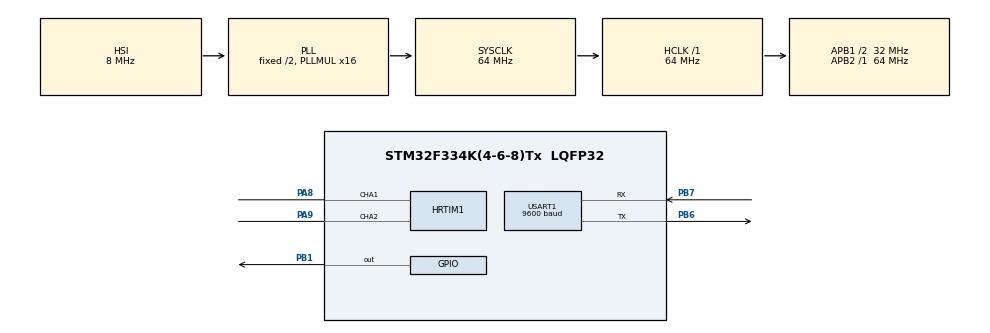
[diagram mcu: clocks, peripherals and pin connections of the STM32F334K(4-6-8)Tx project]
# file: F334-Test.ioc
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HRTIM1.CompareUnit1-Output_TA1TA2=HRTIM_COMPAREUNIT_1
HRTIM1.CompareUnit2-Output_TA1TA2=__NULL
HRTIM1.CompareValue1-Output_TA1TA2=96
HRTIM1.CompareValue2-Output_TA1TA2=5000
HRTIM1.Configuration_TA=Waveform
HRTIM1.DeadTimeInsertion-Output_TA1TA2=HRTIM_TIMDEADTIMEINSERTION_ENABLED
HRTIM1.Deadtimeconfig-Output_TA1TA2=HRTIM_TIMERINDEX_TIMER_A
HRTIM1.FallingValue-Output_TA1TA2=400
HRTIM1.InterruptRequests1-Output_TA1TA2=HRTIM_TIM_IT_UPD
HRTIM1.NumberInterruptRequests-Output_TA1TA2=1
HRTIM1.NumberResetSource1-Output_TA1TA2=1
HRTIM1.NumberResetSource2_TA=0
HRTIM1.NumberSetSource1-Output_TA1TA2=1
HRTIM1.NumberSetSource2_TA=0
HRTIM1.PWMChannel_TA1=HRTIM_OUTPUT_TA1
HRTIM1.PWMChannel_TA2=HRTIM_OUTPUT_TA2
HRTIM1.PWMPolarity_TA2=HRTIM_OUTPUTPOLARITY_LOW
HRTIM1.PWMPulse_TA1=5000
HRTIM1.Periode_MASTER=40960
HRTIM1.Periode_TA=40960
HRTIM1.Polarity2-Output_TA1TA2=HRTIM_OUTPUTPOLARITY_HIGH
HRTIM1.PreloadEnable-Output_TA1TA2=HRTIM_PRELOAD_ENABLED
HRTIM1.PrescalerDead-Output_TA1TA2=HRTIM_TIMDEADTIME_PRESCALERRATIO_MUL8
HRTIM1.RepetitionUpdate-Output_TA1TA2=HRTIM_UPDATEONREPETITION_ENABLED
HRTIM1.ResetOutput1_Source1-Output_TA1TA2=HRTIM_OUTPUTRESET_TIMCMP1
HRTIM1.ResetOutput2_Source1-Output_TA1TA2=HRTIM_OUTPUTRESET_TIMCMP1
HRTIM1.RisingValue-Output_TA1TA2=400
HRTIM1.SetOutput1_Source1-Output_TA1TA2=HRTIM_OUTPUTSET_TIMPER
HRTIM1.SetOutput2_Source1-Output_TA1TA2=HRTIM_OUTPUTSET_TIMCMP1
Mcu.Family=STM32F3
Mcu.Name=STM32F334K(4-6-8)Tx
Mcu.Package=LQFP32
NVIC.HRTIM1_TIMA_IRQn=true\:0\:0\:false\:false\:true\:true\:true
NVIC.PriorityGroup=NVIC_PRIORITYGROUP_3
PA13.Mode=Serial_Wire
PA13.Signal=SYS_JTMS-SWDIO
PA14.Mode=Serial_Wire
PA14.Signal=SYS_JTCK-SWCLK
PA8.Mode=Output_TA1TA2
PA8.Signal=HRTIM1_CHA1
PA9.Mode=Output_TA1TA2
PA9.Signal=HRTIM1_CHA2
PB1.GPIO_Speed=GPIO_SPEED_FREQ_HIGH
PB1.Signal=GPIO_Output
PB6.Mode=Asynchronous
PB6.Signal=USART1_TX
PB7.Mode=Asynchronous
PB7.Signal=USART1_RX
ProjectManager.HeapSize=0x200
ProjectManager.StackSize=0x400
ProjectManager.TargetToolchain=Makefile
RCC.AHBFreq_Value=64000000
RCC.APB1CLKDivider=RCC_HCLK_DIV2
RCC.APB1Freq_Value=32000000
RCC.APB1TimFreq_Value=64000000
RCC.APB2Freq_Value=64000000
RCC.APB2TimFreq_Value=64000000
RCC.CortexFreq_Value=64000000
RCC.HCLKFreq_Value=64000000
RCC.HRTIMSelection=RCC_HRTIM1CLK_PLLCLK
RCC.HSE_VALUE=8000000
RCC.HSI_VALUE=8000000
RCC.PLLMUL=RCC_PLL_MUL16
RCC.SYSCLKFreq_VALUE=64000000
RCC.SYSCLKSourceVirtual=RCC_SYSCLKSOURCE_PLLCLK
USART1.BaudRate=9600
USART1.OverrunDisableParam=ADVFEATURE_OVERRUN_DISABLE
USART1.VirtualMode-Asynchronous=VM_ASYNC
VP_HRTIM1_VS_hrtimMasterTimerNoOutput.Mode=MasterTimer
board=custom

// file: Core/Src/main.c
/* USER CODE BEGIN Header */
/**
 ******************************************************************************
 * @file           : main.c
 * @brief          : Main program body
 ******************************************************************************
 * @attention
 *
 * <h2><center>&copy; Copyright (c) 2021 STMicroelectronics.
 * All rights reserved.</center></h2>
 *
 * This software component is licensed by ST under BSD 3-Clause license,
 * the "License"; You may not use this file except in compliance with the
 * License. You may obtain a copy of the License at:
 *                        opensource.org/licenses/BSD-3-Clause
 *
 ******************************************************************************
 */
/* USER CODE END Header */
#include "main.h"
#include "hrtim.h"
#include "usart.h"
#include "gpio.h"

/* USER CODE BEGIN Includes */
#include "utils.hpp"
#include <cstdint>
#include <stdio.h>
#include "main_cycle.hpp"
/* USER CODE END Includes */

void SystemClock_Config(void);

int main(void)
{

  /* MCU Configuration--------------------------------------------------------*/

  /* Reset of all peripherals, Initializes the Flash interface and the Systick. */
  HAL_Init();

  /* Configure the system clock */
  SystemClock_Config();

  /* Initialize all configured peripherals */
  MX_GPIO_Init();
  MX_USART1_UART_Init();
  MX_HRTIM1_Init();
  /* USER CODE BEGIN 2 */

    main_loop();

  /* USER CODE END 2 */

  /* Infinite loop */
    while (1) {

    }
}

void SystemClock_Config(void)
{
  RCC_OscInitTypeDef RCC_OscInitStruct = {0};
  RCC_ClkInitTypeDef RCC_ClkInitStruct = {0};
  RCC_PeriphCLKInitTypeDef PeriphClkInit = {0};

  /** Initializes the RCC Oscillators according to the specified parameters
  * in the RCC_OscInitTypeDef structure.
  */
  RCC_OscInitStruct.OscillatorType = RCC_OSCILLATORTYPE_HSI;
  RCC_OscInitStruct.HSIState = RCC_HSI_ON;
  RCC_OscInitStruct.HSICalibrationValue = RCC_HSICALIBRATION_DEFAULT;
  RCC_OscInitStruct.PLL.PLLState = RCC_PLL_ON;
  RCC_OscInitStruct.PLL.PLLSource = RCC_PLLSOURCE_HSI;
  RCC_OscInitStruct.PLL.PLLMUL = RCC_PLL_MUL16;
  if (HAL_RCC_OscConfig(&RCC_OscInitStruct) != HAL_OK)
  {
    Error_Handler();
  }
  /** Initializes the CPU, AHB and APB buses clocks
  */
  RCC_ClkInitStruct.ClockType = RCC_CLOCKTYPE_HCLK|RCC_CLOCKTYPE_SYSCLK
                              |RCC_CLOCKTYPE_PCLK1|RCC_CLOCKTYPE_PCLK2;
  RCC_ClkInitStruct.SYSCLKSource = RCC_SYSCLKSOURCE_PLLCLK;
  RCC_ClkInitStruct.AHBCLKDivider = RCC_SYSCLK_DIV1;
  RCC_ClkInitStruct.APB1CLKDivider = RCC_HCLK_DIV2;
  RCC_ClkInitStruct.APB2CLKDivider = RCC_HCLK_DIV1;

  if (HAL_RCC_ClockConfig(&RCC_ClkInitStruct, FLASH_LATENCY_2) != HAL_OK)
  {
    Error_Handler();
  }
  PeriphClkInit.PeriphClockSelection = RCC_PERIPHCLK_HRTIM1|RCC_PERIPHCLK_USART1;
  PeriphClkInit.Usart1ClockSelection = RCC_USART1CLKSOURCE_PCLK1;
  PeriphClkInit.Hrtim1ClockSelection = RCC_HRTIM1CLK_PLLCLK;
  if (HAL_RCCEx_PeriphCLKConfig(&PeriphClkInit) != HAL_OK)
  {
    Error_Handler();
  }
}

void Error_Handler(void)
{
    __disable_irq();
    while (1) {
    }
}
